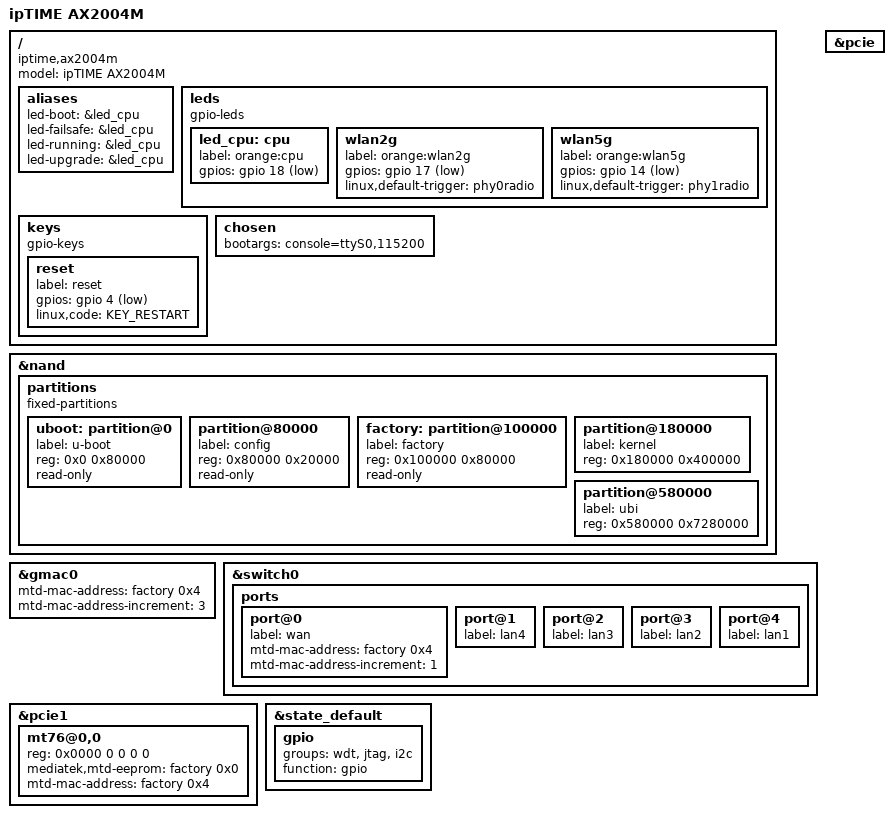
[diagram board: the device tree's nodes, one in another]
// SPDX-License-Identifier: GPL-2.0-or-later OR MIT

#include "mt7621.dtsi"

#include <dt-bindings/gpio/gpio.h>
#include <dt-bindings/input/input.h>

/ {
	compatible = "iptime,ax2004m", "mediatek,mt7621-soc";
	model = "ipTIME AX2004M";

	aliases {
		led-boot = &led_cpu;
		led-failsafe = &led_cpu;
		led-running = &led_cpu;
		led-upgrade = &led_cpu;
	};

	leds {
		compatible = "gpio-leds";

		led_cpu: cpu {
			label = "orange:cpu";
			gpios = <&gpio 18 GPIO_ACTIVE_LOW>;
		};

		wlan2g {
			label = "orange:wlan2g";
			gpios = <&gpio 17 GPIO_ACTIVE_LOW>;
			linux,default-trigger = "phy0radio";
		};

		wlan5g {
			label = "orange:wlan5g";
			gpios = <&gpio 14 GPIO_ACTIVE_LOW>;
			linux,default-trigger = "phy1radio";
		};
	};

	keys {
		compatible = "gpio-keys";

		reset {
			label = "reset";
			gpios = <&gpio 4 GPIO_ACTIVE_LOW>;
			linux,code = <KEY_RESTART>;
		};
	};

	chosen {
		bootargs = "console=ttyS0,115200";
	};
};

&nand {
	status = "okay";

	partitions {
		compatible = "fixed-partitions";
		#address-cells = <1>;
		#size-cells = <1>;

		uboot: partition@0 {
			label = "u-boot";
			reg = <0x0 0x80000>;
			read-only;
		};

		partition@80000 {
			label = "config";
			reg = <0x80000 0x20000>;
			read-only;
		};

		factory: partition@100000 {
			label = "factory";
			reg = <0x100000 0x80000>;
			read-only;
		};

		partition@180000 {
			label = "kernel";
			reg = <0x180000 0x400000>;
		};

		partition@580000 {
			label = "ubi";
			reg = <0x580000 0x7280000>;
		};
	};
};

&gmac0 {
	mtd-mac-address = <&factory 0x4>;
	mtd-mac-address-increment = <3>;
};

&switch0 {
	ports {
		port@0 {
			status = "okay";
			label = "wan";
			mtd-mac-address = <&factory 0x4>;
			mtd-mac-address-increment = <1>;
		};

		port@1 {
			status = "okay";
			label = "lan4";
		};

		port@2 {
			status = "okay";
			label = "lan3";
		};

		port@3 {
			status = "okay";
			label = "lan2";
		};

		port@4 {
			status = "okay";
			label = "lan1";
		};
	};
};

&pcie {
	status = "okay";
};

&pcie1 {
	mt76@0,0 {
		reg = <0x0000 0 0 0 0>;
		mediatek,mtd-eeprom = <&factory 0x0>;
		mtd-mac-address = <&factory 0x4>;
	};
};

&state_default {
	gpio {
		groups = "wdt", "jtag", "i2c";
		function = "gpio";
	};
};
